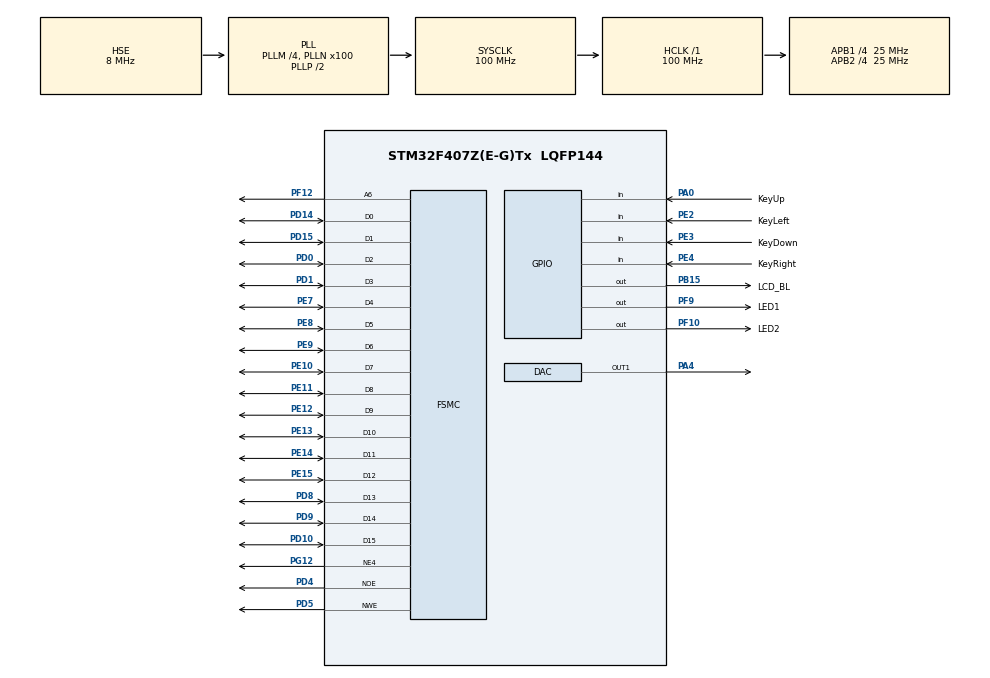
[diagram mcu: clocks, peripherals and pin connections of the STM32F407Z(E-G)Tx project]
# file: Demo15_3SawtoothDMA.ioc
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DAC.DAC_Trigger=DAC_TRIGGER_T6_TRGO
DAC.WaveGeneration=DISABLE
Dma.DAC1.0.Direction=DMA_MEMORY_TO_PERIPH
Dma.DAC1.0.FIFOMode=DMA_FIFOMODE_DISABLE
Dma.DAC1.0.Instance=DMA1_Stream5
Dma.DAC1.0.MemDataAlignment=DMA_MDATAALIGN_WORD
Dma.DAC1.0.MemInc=DMA_MINC_ENABLE
Dma.DAC1.0.Mode=DMA_CIRCULAR
Dma.DAC1.0.PeriphDataAlignment=DMA_PDATAALIGN_WORD
Dma.DAC1.0.PeriphInc=DMA_PINC_DISABLE
Dma.DAC1.0.Priority=DMA_PRIORITY_MEDIUM
Dma.Request0=DAC1
FSMC.AccessMode4=FSMC_ACCESS_MODE_A
FSMC.AddressSetupTime4=2
FSMC.BusTurnAroundDuration4=0
FSMC.DataSetupTime4=16
FSMC.ExtendedAccessMode4=FSMC_ACCESS_MODE_A
FSMC.ExtendedAddressSetupTime4=4
FSMC.ExtendedBusTurnAroundDuration4=0
FSMC.ExtendedDataSetupTime4=9
FSMC.ExtendedMode4=FSMC_EXTENDED_MODE_ENABLE
FSMC.NSBank4=FSMC_NORSRAM_BANK4
FSMC.WriteOperation4=FSMC_WRITE_OPERATION_ENABLE
Mcu.Family=STM32F4
Mcu.Name=STM32F407Z(E-G)Tx
Mcu.Package=LQFP144
NVIC.DMA1_Stream5_IRQn=true\:0\:0\:false\:false\:true\:false\:true\:true
NVIC.PriorityGroup=NVIC_PRIORITYGROUP_4
PA0-WKUP.GPIO_Label=KeyUp
PA0-WKUP.GPIO_PuPd=GPIO_PULLDOWN
PA0-WKUP.Signal=GPIO_Input
PA13.Mode=Serial_Wire
PA13.Signal=SYS_JTMS-SWDIO
PA14.Mode=Serial_Wire
PA14.Signal=SYS_JTCK-SWCLK
PA4.Signal=COMP_DAC1_group
PB15.GPIO_Label=LCD_BL
PB15.PinState=GPIO_PIN_RESET
PB15.Signal=GPIO_Output
PC14-OSC32_IN.Mode=LSE-External-Oscillator
PC14-OSC32_IN.Signal=RCC_OSC32_IN
PC15-OSC32_OUT.Mode=LSE-External-Oscillator
PC15-OSC32_OUT.Signal=RCC_OSC32_OUT
PD0.Signal=FSMC_D2_DA2
PD1.Signal=FSMC_D3_DA3
PD10.Signal=FSMC_D15_DA15
PD14.Signal=FSMC_D0_DA0
PD15.Signal=FSMC_D1_DA1
PD4.Signal=FSMC_NOE
PD5.Signal=FSMC_NWE
PD8.Signal=FSMC_D13_DA13
PD9.Signal=FSMC_D14_DA14
PE10.Signal=FSMC_D7_DA7
PE11.Signal=FSMC_D8_DA8
PE12.Signal=FSMC_D9_DA9
PE13.Signal=FSMC_D10_DA10
PE14.Signal=FSMC_D11_DA11
PE15.Signal=FSMC_D12_DA12
PE2.GPIO_Label=KeyLeft
PE2.GPIO_PuPd=GPIO_PULLUP
PE2.Signal=GPIO_Input
PE3.GPIO_Label=KeyDown
PE3.GPIO_PuPd=GPIO_PULLUP
PE3.Signal=GPIO_Input
PE4.GPIO_Label=KeyRight
PE4.GPIO_PuPd=GPIO_PULLUP
PE4.Signal=GPIO_Input
PE7.Signal=FSMC_D4_DA4
PE8.Signal=FSMC_D5_DA5
PE9.Signal=FSMC_D6_DA6
PF10.GPIO_Label=LED2
PF10.Signal=GPIO_Output
PF12.Signal=FSMC_A6
PF9.GPIO_Label=LED1
PF9.Signal=GPIO_Output
PG12.Mode=NorPsramChipSelect4_4
PG12.Signal=FSMC_NE4
PH0-OSC_IN.Mode=HSE-External-Oscillator
PH0-OSC_IN.Signal=RCC_OSC_IN
PH1-OSC_OUT.Mode=HSE-External-Oscillator
PH1-OSC_OUT.Signal=RCC_OSC_OUT
ProjectManager.HeapSize=0x200
ProjectManager.StackSize=0x400
ProjectManager.TargetToolchain=STM32CubeIDE
RCC.48MHZClocksFreq_Value=50000000
RCC.AHBFreq_Value=100000000
RCC.APB1CLKDivider=RCC_HCLK_DIV4
RCC.APB1Freq_Value=25000000
RCC.APB1TimFreq_Value=50000000
RCC.APB2CLKDivider=RCC_HCLK_DIV4
RCC.APB2Freq_Value=25000000
RCC.APB2TimFreq_Value=50000000
RCC.CortexFreq_Value=100000000
RCC.FLatency=FLASH_LATENCY_3
RCC.HCLKFreq_Value=100000000
RCC.HSE_VALUE=8000000
RCC.HSI_VALUE=16000000
RCC.PLLM=4
RCC.PLLN=100
RCC.PLLSourceVirtual=RCC_PLLSOURCE_HSE
RCC.SYSCLKFreq_VALUE=100000000
RCC.SYSCLKSource=RCC_SYSCLKSOURCE_PLLCLK
RCC.VCOOutputFreq_Value=200000000
SH.COMP_DAC1_group.0=DAC_OUT1,DAC_OUT1
SH.FSMC_A6.0=FSMC_A6,A6_4
SH.FSMC_D0_DA0.0=FSMC_D0,16b-d4
SH.FSMC_D10_DA10.0=FSMC_D10,16b-d4
SH.FSMC_D11_DA11.0=FSMC_D11,16b-d4
SH.FSMC_D12_DA12.0=FSMC_D12,16b-d4
SH.FSMC_D13_DA13.0=FSMC_D13,16b-d4
SH.FSMC_D14_DA14.0=FSMC_D14,16b-d4
SH.FSMC_D15_DA15.0=FSMC_D15,16b-d4
SH.FSMC_D1_DA1.0=FSMC_D1,16b-d4
SH.FSMC_D2_DA2.0=FSMC_D2,16b-d4
SH.FSMC_D3_DA3.0=FSMC_D3,16b-d4
SH.FSMC_D4_DA4.0=FSMC_D4,16b-d4
SH.FSMC_D5_DA5.0=FSMC_D5,16b-d4
SH.FSMC_D6_DA6.0=FSMC_D6,16b-d4
SH.FSMC_D7_DA7.0=FSMC_D7,16b-d4
SH.FSMC_D8_DA8.0=FSMC_D8,16b-d4
SH.FSMC_D9_DA9.0=FSMC_D9,16b-d4
SH.FSMC_NOE.0=FSMC_NOE,Lcd4
SH.FSMC_NWE.0=FSMC_NWE,Lcd4
TIM6.Period=10-1
TIM6.Prescaler=500-1
TIM6.TIM_MasterOutputTrigger=TIM_TRGO_UPDATE
VP_TIM6_VS_ClockSourceINT.Mode=Enable_Timer
board=custom

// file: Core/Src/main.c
/* USER CODE BEGIN Header */
/**
  ******************************************************************************
  * @file           : main.c
  * @brief          : Main program body
  ******************************************************************************
  * @attention
  *
  * Copyright (c) 2023 STMicroelectronics.
  * All rights reserved.
  *
  * This software is licensed under terms that can be found in the LICENSE file
  * in the root directory of this software component.
  * If no LICENSE file comes with this software, it is provided AS-IS.
  *
  ******************************************************************************
  */
/* USER CODE END Header */
#include "main.h"
#include "dac.h"
#include "dma.h"
#include "tim.h"
#include "gpio.h"
#include "fsmc.h"

/* USER CODE BEGIN Includes */
#include "lcd.h"
#include "keyled.h"
/* USER CODE END Includes */

void SystemClock_Config(void);

int main(void)
{

  /* MCU Configuration--------------------------------------------------------*/

  /* Reset of all peripherals, Initializes the Flash interface and the Systick. */
  HAL_Init();

  /* Configure the system clock */
  SystemClock_Config();

  /* Initialize all configured peripherals */
  MX_GPIO_Init();
  MX_DMA_Init();
  MX_FSMC_Init();
  MX_DAC_Init();
  MX_TIM6_Init();
  /* USER CODE BEGIN 2 */
  lcd_init();
  lcd_show_str(10, 10, 24, "Demo15_3: DAC output with DMA", RED);
  lcd_show_str(10, 40, 24, "Sawtooth wave on PA4", RED);
  lcd_show_str(10, 70, 24, "Wave's interval is 100ms", RED);

  uint32_t userWave[1000];
  userWave[0] = 0;
  for (uint16_t i = 1; i < 1000; ++i) {
	  userWave[i] = userWave[i - 1] + 4;
  }
  HAL_DAC_Start_DMA(&hdac, DAC_CHANNEL_1, userWave, 1000, DAC_ALIGN_12B_R);
  HAL_TIM_Base_Start(&htim6);

  /* USER CODE END 2 */

  /* Infinite loop */
  while (1)
  {

  }
}

void SystemClock_Config(void)
{
  RCC_OscInitTypeDef RCC_OscInitStruct = {0};
  RCC_ClkInitTypeDef RCC_ClkInitStruct = {0};

  /** Configure the main internal regulator output voltage
  */
  __HAL_RCC_PWR_CLK_ENABLE();
  __HAL_PWR_VOLTAGESCALING_CONFIG(PWR_REGULATOR_VOLTAGE_SCALE1);

  /** Initializes the RCC Oscillators according to the specified parameters
  * in the RCC_OscInitTypeDef structure.
  */
  RCC_OscInitStruct.OscillatorType = RCC_OSCILLATORTYPE_HSE;
  RCC_OscInitStruct.HSEState = RCC_HSE_ON;
  RCC_OscInitStruct.PLL.PLLState = RCC_PLL_ON;
  RCC_OscInitStruct.PLL.PLLSource = RCC_PLLSOURCE_HSE;
  RCC_OscInitStruct.PLL.PLLM = 4;
  RCC_OscInitStruct.PLL.PLLN = 100;
  RCC_OscInitStruct.PLL.PLLP = RCC_PLLP_DIV2;
  RCC_OscInitStruct.PLL.PLLQ = 4;
  if (HAL_RCC_OscConfig(&RCC_OscInitStruct) != HAL_OK)
  {
    Error_Handler();
  }

  /** Initializes the CPU, AHB and APB buses clocks
  */
  RCC_ClkInitStruct.ClockType = RCC_CLOCKTYPE_HCLK|RCC_CLOCKTYPE_SYSCLK
                              |RCC_CLOCKTYPE_PCLK1|RCC_CLOCKTYPE_PCLK2;
  RCC_ClkInitStruct.SYSCLKSource = RCC_SYSCLKSOURCE_PLLCLK;
  RCC_ClkInitStruct.AHBCLKDivider = RCC_SYSCLK_DIV1;
  RCC_ClkInitStruct.APB1CLKDivider = RCC_HCLK_DIV4;
  RCC_ClkInitStruct.APB2CLKDivider = RCC_HCLK_DIV4;

  if (HAL_RCC_ClockConfig(&RCC_ClkInitStruct, FLASH_LATENCY_3) != HAL_OK)
  {
    Error_Handler();
  }
}

/* USER CODE BEGIN 4 */
void HAL_DAC_ConvCpltCallbackCh1(DAC_HandleTypeDef *hdac) {
	LED1_Toggle();
}
/* USER CODE END 4 */

void Error_Handler(void)
{
  __disable_irq();
  while (1)
  {
  }
}
